# psc3m6 register map
Vendor: Infineon Technologies; Series: PSC3M6; File version: 1.0
CPU: CM33 r0p1, little endian, MPU, FPU, DSP, VTOR, 3 interrupt priority bits, 167 interrupts
Registers are 32-bit, read-write, reset 0x0 unless marked. A register's access mark holds for its fields unless they carry their own. Offsets are from the block's base; [hi:lo] are bit positions; lines under a group give offsets from that group; {n}, {i} and the like mark numbered series.

## HPPASS (part 2 of 3) — Top Level of MCPASS IP
Base 0x42B00000
0x90000 DAC_BUFFER group — DAC + Buffer IP
  {0x0+0x400*j} DAC_BUFFER[{j}] (j=0..1) group — Individual DAC Buffer Configuration Registers
    0x00 DAC_BUFFER_FIFO_DATA_IN — Input data for DAC Buffer Fifo
      [31:0] INPUT_DATA — DAC Data from Direct Write Mode of Operation. Data Access Mode of Operation: Single Word LSB Alignment: Data[11:0] Single Word MSB Alignment: Data[31:20] Double Word Access LSB Alignment: Word 0: Data[11:0], Word 1[27:16] Double Word Access MSB Alignment: Word 0: Data[15:4], Word 1[31:20] Bits outside of these configurations shall return 0x0. The various fields shall map to the same underlying hardware.
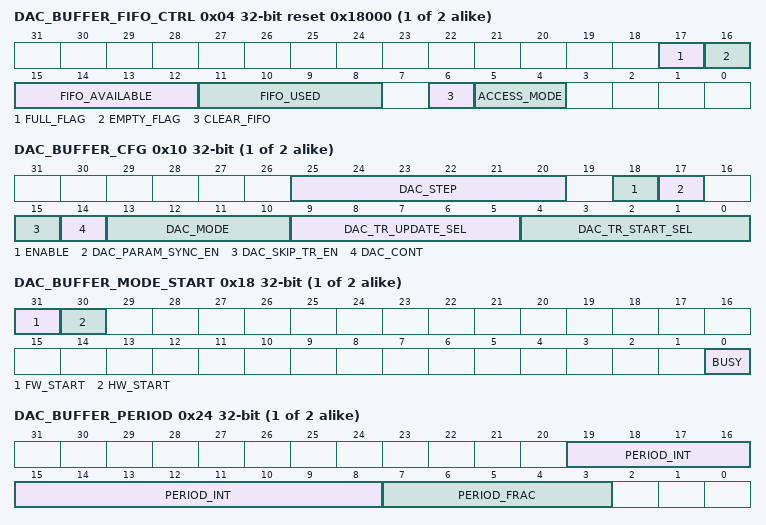
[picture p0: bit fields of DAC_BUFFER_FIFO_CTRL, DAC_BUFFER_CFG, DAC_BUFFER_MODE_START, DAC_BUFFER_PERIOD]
    0x04 DAC_BUFFER_FIFO_CTRL reset 0x18000 — DAC Buffer Fifo control and configuration
      [17] FULL_FLAG ro — Flag to indicate if the Fifo is Full. This flag will be asserted when there is 0 room for data available during Single Word access mode. This flag will be asserted when there is room for 0 or 1 words available during Double Word access mode.
      [16] EMPTY_FLAG ro — Flag to indicate if the Fifo is Empty
      [15:12] FIFO_AVAILABLE ro — the amount of the file available
      [11:8] FIFO_USED ro — The amount of the Fifo used
      [6] CLEAR_FIFO write-1-sets — Firmware sets this bit to clear all Fifo entries and reset the Read and Write Pointers. Hardware Clears this bit.
      [5:4] ACCESS_MODE — 0: Single Word LSB Aligned 1: Single Word MSB Aligned 2: Double Word LSB Aligned 3: Double Word MSB Aligned
    0x10 DAC_BUFFER_CFG — DAC Buffer Control Register
      [25:20] DAC_STEP — Static value of 6 bit DAC step size. Step size is DAC_STEP +1 (default is '1') , range is 1 - 64, only valid in SLOPE/LUT modes. NOTE: In LUT mode each step jumps to a new LUT value on WORD boundaries. So for example: DAC_STEP = 0 (default Step size of 1) advances the LUT address by 4 (LUT WORD boundary) DAC_STEP = 1 (Step size of 2) advances the LUT address by 8, etc
      [18] ENABLE — Global Enable Signal for DAC Buffer Digital instance. This bit must be set before setting any other registers as it is tied to got DAC Reset.
      [17] DAC_PARAM_SYNC_EN — Parameter Sync Enable. 0: Disabled. Always update parameters on DAC trigger (as defined by DAC_MODE) 1: Enabled. Only update parameters on DAC trigger if DAC_PARAM_SYNC.READY is set.
      [15] DAC_SKIP_TR_EN — Skip the first DAC hardware update trigger afer a mode is enabled. Allows for a minimum of a full trigger period before the first hardware update occurs. This bit should only be set before operations begin. It should remain set during operation as well. 0: First trigger following DAC_MODE_EN updates the DAC value. 1: First trigger following DAC_MODE_EN is skipped. Following trigger updates the DAC value.
      [14] DAC_CONT — DAC Continuous Mode (Only valid for Slope and LUT modes) 0: Slope/LUT operation is One-Shot, last output value is held 1: Slope/LUT operation is Continuous, operation is restarted when end value is reached
      [13:10] DAC_MODE — DAC Operating Mode. This setting may only be changed when the mode is disabled. See DAC_MODE_START.
        0=BUFFERED (Single Value Buffered Mode); 1=HYSTERETIC (Two Value Hysteretic Buffered Mode); 2=SLOPE_RISING (Rising Slope Mode); 3=SLOPE_FALLING (Falling Slope Mode); 4=SLOPE_TRIANGULAR (Triangular Slope Mode); 5=LUT_FORWARD (LUT Forward Mode); 6=LUT_REVERSE (LUT Reverse Mode); 7=LUT_FWD_REV (LUT Forward Reverse Mode); 8=FIFO (Source the Data from the Fifo); 9=ADC_LOOPBACK (Source the Data from the ADC Loopback mechanism)
      [9:5] DAC_TR_UPDATE_SEL — DAC Trigger Update Select. Select one of the triggers or internal events. See DAC_MODE for detailed operation. If one of the MCPASS HW or FW triggers are selected (see INFRA), then the trigger must be PULSE mode. In addition, the maximum frequency of the active trigger edge must be less than or equal to CSG CLOCK/2 (every other clock).
        0=DISABLED (N/A); 1=TR0 (HW (or FW) input triggers); {v}=TR{v-1} (N/A) (v=2..8); 9=TR8 (HW (or FW) input triggers); {v}=TR{v-1} (N/A) (v=10..16); 17=DAC_PERIOD_TC (Period terminal count. Period divider value is programmed in DAC_PERIOD register)
      [4:0] DAC_TR_START_SEL — DAC Trigger Start Select. Select one of the MCPASS HW or FW triggers. Trigger must be PULSE mode (see INFRA). See DAC_MODE_START register to select this as the DAC start trigger.
        0=DISABLED (N/A); 1=TR0 (HW (or FW) input triggers); {v}=TR{v-1} (N/A) (v=2..8); 9=TR8 (HW (or FW) input triggers); {v}=TR{v-1} (N/A) (v=10..16)
    0x14 DAC_BUFFER_PARAM_SYNC — DAC Parameter Synchronized Update
      [0] READY write-1-sets — Use this bit to synchronize the update of multiple DAC parameters. If DAC_PARAM_SYNC_EN bit is '1', then set this bit after writes to all parameter registers (VAL_A, VAL_B, DAC_PERIOD, DAC_STEP) are complete to synchronize parameter update on a subsequent DAC trigger This allows for writes to multiple registers to be written before new parameters are updated to avoid partial updates. This bit is cleared by HW on the parameter update event. if DAC_PARAM_SYNC_EN is '0', this bit is ignored and parameters are updated on the following UPDATE trigger. NOTE: This bit can be used in conjunction with DAC_CASCADE_EN to synchronize the parameter update of multiple CSG slices.
    0x18 DAC_BUFFER_MODE_START — DAC Mode Start
      [31] FW_START — 1: Starts the selected mode on this FW write. 0: Stops the selected mode. When this bit is cleared, the current DAC_VAL will not change unless it is over-written directly - or a new DAC mode is started. This field is automatically reset to '0' on DAC_SLOPE_DONE event (unless DAC_CONT is set for continous mode).
      [30] HW_START — 1: Wait for subsequent DAC_START_TR to start the selected mode. 0: Stops the selected mode. When this bit is cleared, the current DAC_VAL will not change unless it is over-written directly - or a new DAC mode is started. This field is automatically reset to '0' on DAC_SLOPE_DONE event (unless DAC_CONT is set for continous mode).
      [0] BUSY ro — Read only bit to indicate that a DAC MODE has been enabled and is currently in progress. If FW_START is used to start the mode, then the FW_START bit is equivalent to this bit and low when the mode is completed or stopped. If HW_START is used to start the mode, then this status bit goes high on the DAC_START_TR event, and low when the mode is completed or stopped. NOTE: This read only bit refects the state of the DAC controller which is reset in DeepSleep and therefore this bit is not a retention bit.
    0x1C DAC_BUFFER_VAL_A — DAC Vaue A Buffer
      [11:0] VALUE — DAC A Value, usage is mode dependent (see DAC_MODE) NOTE: In LUT modes this is the Start Address of the LUT waveform in byte address format (e.g. 0, 4, 8, ... 1F8, 1FC)
    0x20 DAC_BUFFER_VAL_B — DAC Value B Buffer
      [11:0] VALUE — DAC B Value, usage is mode dependent (see DAC_MODE) NOTE: In LUT modes this is the End Address of the LUT waveform in byte address format (e.g. 0, 4, 8, ... 1F8, 1FC)
    0x24 DAC_BUFFER_PERIOD — DAC Period Buffer
      [19:8] PERIOD_INT — 12-bit Integer Divide Value. Integer count by (1+PERIOD_INT). Allows for integer counts in the range [1, 4096].
      [7:3] PERIOD_FRAC — 5-bit Fractional Divide Value. Allows for fractional count in the range [0, 31/32]
    0x28 DAC_BUFFER_VAL — Firmware Write port (excluding Fifo)
      [11:0] VALUE — Direct drive to DAC Hard IP for output. When DAC_MODE_EN is '0', the value in this register is output. A write to this register also STOPs the current DAC_MODE operation, and subsequent DAC triggers are ignored.
    0x2C DAC_BUFFER_STATUS ro — Read of Current DAC Value
      [11:0] DAC_VAL — Read Only value of current digital DAC output
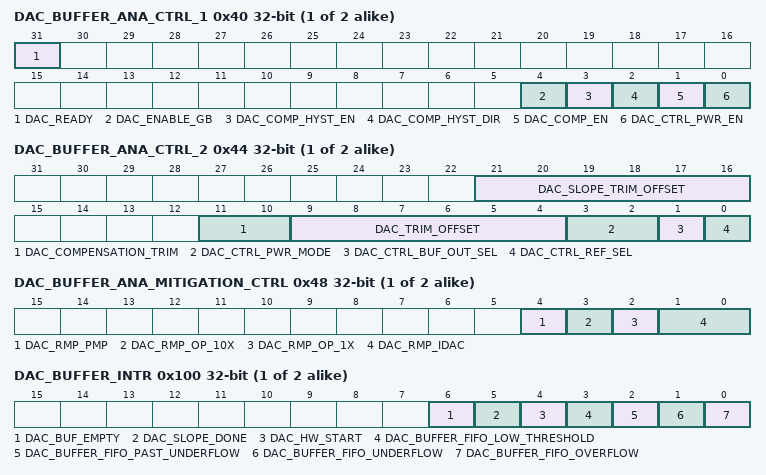
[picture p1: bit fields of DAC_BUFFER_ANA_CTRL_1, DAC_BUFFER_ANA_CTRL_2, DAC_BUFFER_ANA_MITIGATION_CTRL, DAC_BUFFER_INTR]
    0x40 DAC_BUFFER_ANA_CTRL_1 — Control Bits
      [31] DAC_READY ro — DAC Ready Status Monitor
      [4] DAC_ENABLE_GB — Buffer Gain Boost Enable
      [3] DAC_COMP_HYST_EN — Comparator Hysterysis Enable
      [2] DAC_COMP_HYST_DIR — Comparator Hysterysis Direciton
      [1] DAC_COMP_EN — Comparator Enable
      [0] DAC_CTRL_PWR_EN — 0x0: Block is disabled. 0x1: Block is enabled when act_isolate_hv_n = 1 and clk_8m is provided.
    0x44 DAC_BUFFER_ANA_CTRL_2 — Control Bits
      [21:16] DAC_SLOPE_TRIM_OFFSET — Offset Slope Correction Bits for Buffers
      [11:10] DAC_COMPENSATION_TRIM — Compensation Capacitor Setting
      [9:4] DAC_TRIM_OFFSET — dac offset trim (buffer offset trim)
      [3:2] DAC_CTRL_PWR_MODE — Buffer Drive State
      [1] DAC_CTRL_BUF_OUT_SEL — 0x0: Sends Buffered DAC Output to pin, DAC_BUF_OUT_HV, Pad AN[5] 0x1: TBD
      [0] DAC_CTRL_REF_SEL — 0x0: VCCD is DAC reference. 0x1: DAC_VREF_HV is DAC reference.
    0x48 DAC_BUFFER_ANA_MITIGATION_CTRL — Risk Mitigation Control Bits. May be removed in the future.
      [4] DAC_RMP_PMP — Related to use of Pump inside the DAC
      [3] DAC_RMP_OP_10X — Used in 10x mode of the DAC
      [2] DAC_RMP_OP_1X — Used in 1x mode of the DAC
      [1:0] DAC_RMP_IDAC
    0x4C DAC_BUFFER_ANA_DFT_CTRL — ADFT Control bits
      [2:0] DAC_CTRL_ADFT_SEL — ADFT Configuration Bits
        0=DISABLED (Hi-Z); 1=ADFT_SEL_DAC_BUF_OUT_HV (N/A); 2=ADFT_SEL_DAC_BUF_OUT_INT_HV (N/A); 3=ADFT_SEL_VPUMP (Pump feed back voltage); 4=ADFT_SEL_IDC_BUF (N/A); 5=ADFT_SEL_DAC_OUT (N/A); 6=ADFT_SEL_COMP_HV (Offset trim comp output); 7=DISABLED_7 (Hi-Z)
    0x100 DAC_BUFFER_INTR — DAC + Buffer Interrupt register
      [6] DAC_BUF_EMPTY write-1-clears — When BUFFERED or HYSTERETIC mode is enabled, this interrupt is set when there is a DAC UPDATE trigger that transfers the buffered value(s) to active value(s) (see mode operation) and it means that the user may write new values to the buffer registers.
      [5] DAC_SLOPE_DONE write-1-clears — When SLOPE or LUT mode is enabled, this interrupt is set when the SLOPE (or LUT waveform) has completed. This interrupt is also set periodically on the last value of a DAC SLOPE in continuous mode
      [4] DAC_HW_START write-1-clears — This DAC_MODE operation was started with a HW START trigger.
      [3] DAC_BUFFER_FIFO_LOW_THRESHOLD write-1-clears — Set when FIFO is almost empty i.e. FIFO space left with just 3 entries
      [2] DAC_BUFFER_FIFO_PAST_UNDERFLOW write-1-clears — Set when FIFO is empty, but Trigger tries to Pull Data from the empty Fifo.
      [1] DAC_BUFFER_FIFO_UNDERFLOW write-1-clears — Set when FIFO has 0 elements i.e. is empty.
      [0] DAC_BUFFER_FIFO_OVERFLOW write-1-clears — Set once when FIFO reaches full. If no data is pulled from the Fifo, this interrupt shall not continue firing. This interrupt will be asserted when there is 0 room for data available during Single Word access mode. This interrupt will be asserted when there is room for 0 or 1 words available during Double Word access mode.
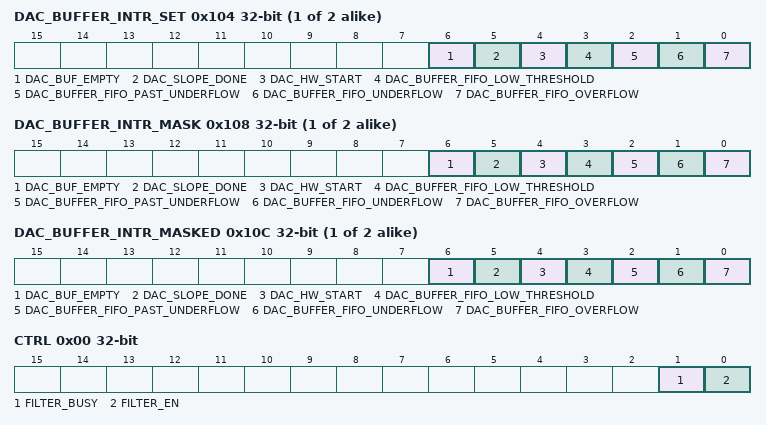
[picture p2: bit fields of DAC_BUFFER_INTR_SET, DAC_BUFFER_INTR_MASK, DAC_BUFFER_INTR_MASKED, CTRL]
    0x104 DAC_BUFFER_INTR_SET — DAC + Buffer Interrupt request set register
      [6] DAC_BUF_EMPTY write-1-sets — Write with '1' to set corresponding bit in interrupt request register.
      [5] DAC_SLOPE_DONE write-1-sets — Write with '1' to set corresponding bit in interrupt request register.
      [4] DAC_HW_START write-1-sets — Write with '1' to set corresponding bit in interrupt request register.
      [3] DAC_BUFFER_FIFO_LOW_THRESHOLD write-1-sets — Write with '1' to set corresponding bit in interrupt request register.
      [2] DAC_BUFFER_FIFO_PAST_UNDERFLOW write-1-sets — Write with '1' to set corresponding bit in interrupt request register.
      [1] DAC_BUFFER_FIFO_UNDERFLOW write-1-sets — Write with '1' to set corresponding bit in interrupt request register.
      [0] DAC_BUFFER_FIFO_OVERFLOW write-1-sets — Write with '1' to set corresponding bit in interrupt request register.
    0x108 DAC_BUFFER_INTR_MASK — DAC + Buffer Interrupt request mask
      [6] DAC_BUF_EMPTY — Mask bit for corresponding bit in interrupt request register.
      [5] DAC_SLOPE_DONE — Mask bit for corresponding bit in interrupt request register.
      [4] DAC_HW_START — Mask bit for corresponding bit in interrupt request register.
      [3] DAC_BUFFER_FIFO_LOW_THRESHOLD — Mask bit for corresponding bit in interrupt request register.
      [2] DAC_BUFFER_FIFO_PAST_UNDERFLOW — Mask bit for corresponding bit in interrupt request register.
      [1] DAC_BUFFER_FIFO_UNDERFLOW — Mask bit for corresponding bit in interrupt request register.
      [0] DAC_BUFFER_FIFO_OVERFLOW — Mask bit for corresponding bit in interrupt request register.
    0x10C DAC_BUFFER_INTR_MASKED ro — DAC + Buffer Interrupt request masked
      [6] DAC_BUF_EMPTY — Logical and of corresponding request and mask bits.
      [5] DAC_SLOPE_DONE — Logical and of corresponding request and mask bits.
      [4] DAC_HW_START — Logical and of corresponding request and mask bits.
      [3] DAC_BUFFER_FIFO_LOW_THRESHOLD — Logical and of corresponding request and mask bits.
      [2] DAC_BUFFER_FIFO_PAST_UNDERFLOW — Logical and of corresponding request and mask bits.
      [1] DAC_BUFFER_FIFO_UNDERFLOW — Logical and of corresponding request and mask bits.
      [0] DAC_BUFFER_FIFO_OVERFLOW — Logical and of corresponding request and mask bits.
    0x200 LUT_DAC_BUFFER group — DAC LUT waveform data
      {0x0+4l} DAC_BUFFER_LUT_DATA[{l}] (l=0..127) reset not defined — LUT Waveform Data
        [11:0] DATA — DAC waveform
0xA0000 MX3P3ZFILT group — 3 Poles - 3 Zeros HW filter
  0x00 HWFILT3P3Z_TOP group — HW Filter 3 Poles 3 Zeros module TOP
    0x00 CTRL — HW Filter 3 Poles 3 Zeros module TOP control register
      [31] HWFILT3P3Z_EN — HWFILT3P3Z_SS peripheral enable: 0 = disable (only mmio CTRL registers is accessible) 1 = enable (all AHB registers in the HWFILT3P3Z_SS are accessible)
  0x100 HWFILT3P3Z group — HW Filter 3 Poles 3 Zeros module
    0x00 CTRL — Filter Control register
      [1] FILTER_BUSY ro — Filter output ready: 1 = busy 0 = free
      [0] FILTER_EN — Enable/Disable Filter: 0 = Disable (all registers are initilaized to the default values) 1 = Enable
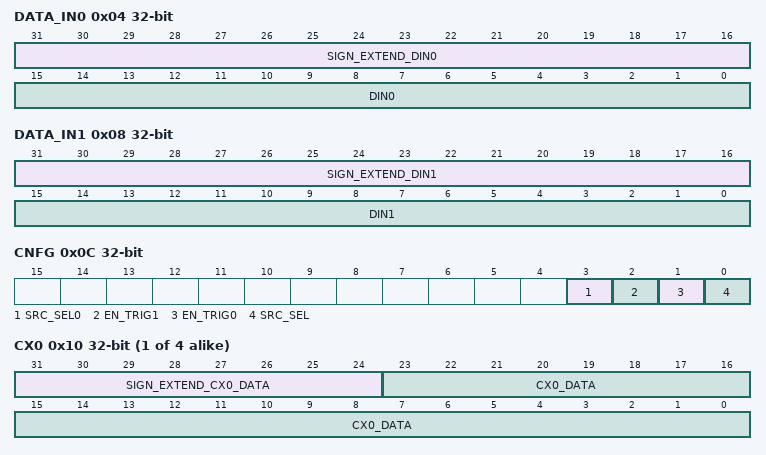
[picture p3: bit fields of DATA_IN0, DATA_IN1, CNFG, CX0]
    0x04 DATA_IN0 — Filter data input 0 register
      [31:16] SIGN_EXTEND_DIN0 ro — Filter Data 0 Input Register sign extended
      [15:0] DIN0 — Filter Data 0 Input Register When writing, the filter processing will start if the corresponding trigger enable bit in the CNFG register is set
    0x08 DATA_IN1 — Filter data input 1 register
      [31:16] SIGN_EXTEND_DIN1 ro — Filter Data 1 Input Register sign extended
      [15:0] DIN1 — Filter Data 1 Input Register When writing, the filter processing will start if the corresponding trigger enable bit in the CNFG register is set
    0x0C CNFG — Filter Configuration register
      [3] SRC_SEL0 — Select source for register DATA_IN0: 0 = AHB IF 1 = DATA PATH
      [2] EN_TRIG1 — Enable/Disable filter processing on writing into register DAT_IN1: 0 = Disable 1 = Enable
      [1] EN_TRIG0 — Enable/Disable filter processing on writing into register DAT_IN0: 0 = Disable 1 = Enable
      [0] SRC_SEL — Select source for register DATA_IN1: 0 = AHB IF 1 = DATA PATH
    {0x10+4k} CX{k} (k=0..3) — Coefficient X{k}
      [31:24] SIGN_EXTEND_CX{k}_DATA ro — Coefficient sign extended
      [23:0] CX{k}_DATA — Coefficient data register
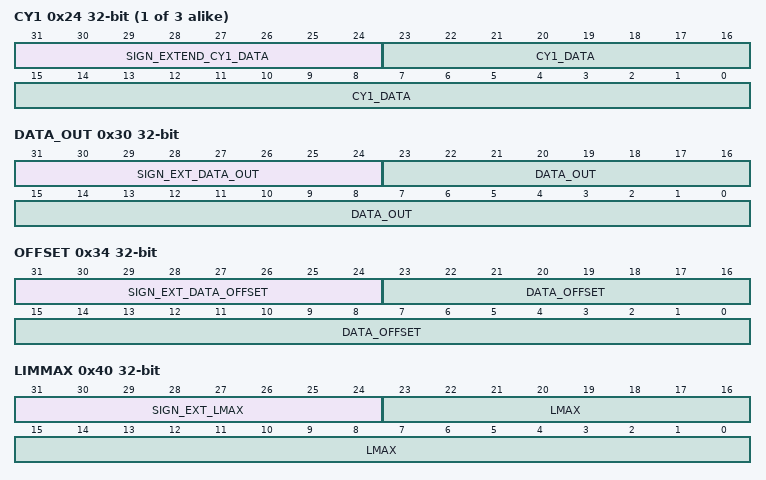
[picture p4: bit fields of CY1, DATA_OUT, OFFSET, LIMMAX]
    {0x20+4k} CY{k} (k=1..3) — Coefficient Y{k}
      [31:24] SIGN_EXTEND_CY{k}_DATA ro — Coefficient sign extended
      [23:0] CY{k}_DATA — Coefficient data register
    0x30 DATA_OUT ro — Filter data output register
      [31:24] SIGN_EXT_DATA_OUT — Filter Data Output Register sign extended
      [23:0] DATA_OUT — Filter Data Output Register
    0x34 OFFSET — Filter offset register
      [31:24] SIGN_EXT_DATA_OFFSET ro — Filter Data Output Offset Register sign extended
      [23:0] DATA_OFFSET — Filter Data Output Offset Register
    0x40 LIMMAX — Filter Out Max Limit register
      [31:24] SIGN_EXT_LMAX ro — Filter Out Max Limit Register sign extended
      [23:0] LMAX — Filter Out Max Limit Register
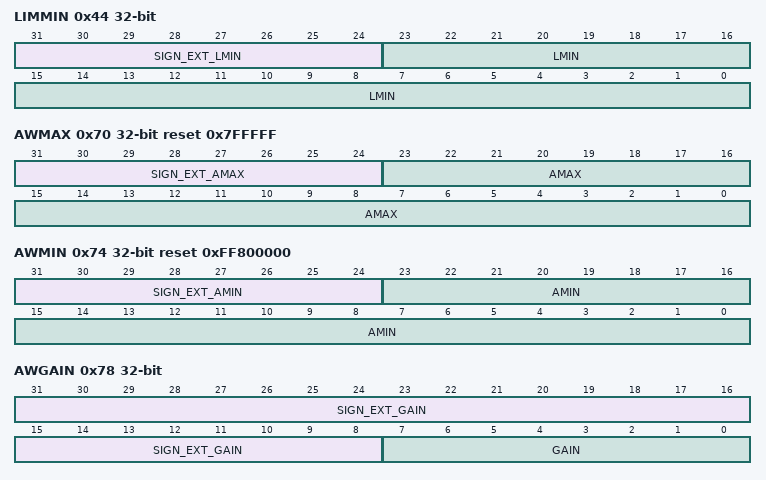
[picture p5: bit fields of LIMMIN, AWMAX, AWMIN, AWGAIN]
    0x44 LIMMIN — Filter Out Min Limit register
      [31:24] SIGN_EXT_LMIN ro — Filter Out Min Limit Register sign extended
      [23:0] LMIN — Filter Out Min Limit Register
    0x60 SCALECX — Scale X coefficients Factor register
      [2:0] SCALE_CX — Scale X Coefficients Factor
    0x64 SCALECY — Scale Y coefficients Factor register
      [2:0] SCALE_CY — Scale Y Coefficients Factor
    0x68 GIN — Amplify Input difference
      [1:0] G_IN — Amplify input difference factor
    0x6C GOUT — Scale Output
      [2:0] G_OUT — Scale down output
    0x70 AWMAX reset 0x7FFFFF — Filter Anti Windup Max Limit register
      [31:24] SIGN_EXT_AMAX ro — FILTER Anti Windup Max Limit register sign extended
      [23:0] AMAX — FILTER Anti Windup Max Limit register
    0x74 AWMIN reset 0xFF800000 — Filter Anti Windup Min Limit register
      [31:24] SIGN_EXT_AMIN ro — FILTER Anti Windup Min Limit register sign extended
      [23:0] AMIN — FILTER Anti Windup Min Limit register
    0x78 AWGAIN — Filter Anti Windup Gain register
      [31:8] SIGN_EXT_GAIN ro — FILTER Anti Windup Gain register sign extended
      [7:0] GAIN — FILTER Anti Windup Gain register: - the minimum allowed negative number has to be 0x81
    0x80 VERSION ro reset 0xC0DE0002 — Filter Version register
      [31:0] VERSION — Filter Version Register
